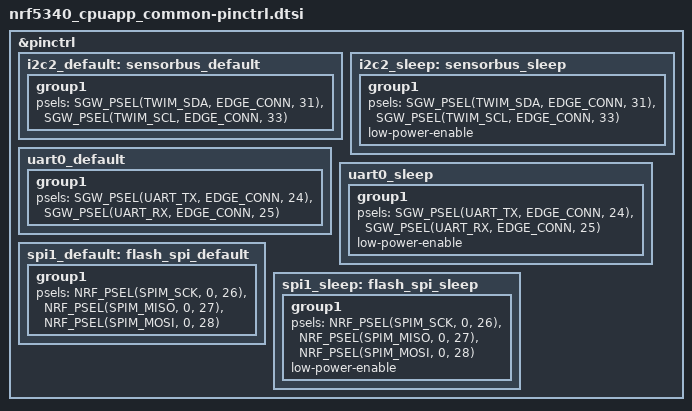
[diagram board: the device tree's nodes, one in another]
/*
 * Copyright (c) 2022 Nordic Semiconductor
 * Copyright (c) 2024 Sensoan Oy
 * SPDX-License-Identifier: Apache-2.0
 */

&pinctrl {
	i2c2_default: sensorbus_default: i2c2_default {
		group1 {
			psels = <SGW_PSEL(TWIM_SDA, EDGE_CONN, 31)>,
				<SGW_PSEL(TWIM_SCL, EDGE_CONN, 33)>;
		};
	};

	i2c2_sleep: sensorbus_sleep:  i2c2_sleep {
		group1 {
			psels = <SGW_PSEL(TWIM_SDA, EDGE_CONN, 31)>,
				<SGW_PSEL(TWIM_SCL, EDGE_CONN, 33)>;
			low-power-enable;
		};
	};

	uart0_default: uart0_default {
		group1 {
			psels = <SGW_PSEL(UART_TX, EDGE_CONN, 24)>,
				<SGW_PSEL(UART_RX, EDGE_CONN, 25)>;
		};
	};

	uart0_sleep: uart0_sleep {
		group1 {
			psels = <SGW_PSEL(UART_TX, EDGE_CONN, 24)>,
				<SGW_PSEL(UART_RX, EDGE_CONN, 25)>;
			low-power-enable;
		};
	};

	spi1_default: flash_spi_default: spi1_default {
		group1 {
			psels = <NRF_PSEL(SPIM_SCK, 0, 26)>,
				<NRF_PSEL(SPIM_MISO, 0, 27)>,
				<NRF_PSEL(SPIM_MOSI, 0, 28)>;
		};
	};

	spi1_sleep: flash_spi_sleep: spi1_sleep {
		group1 {
			psels = <NRF_PSEL(SPIM_SCK, 0, 26)>,
				<NRF_PSEL(SPIM_MISO, 0, 27)>,
				<NRF_PSEL(SPIM_MOSI, 0, 28)>;
			low-power-enable;
		};
	};
};
